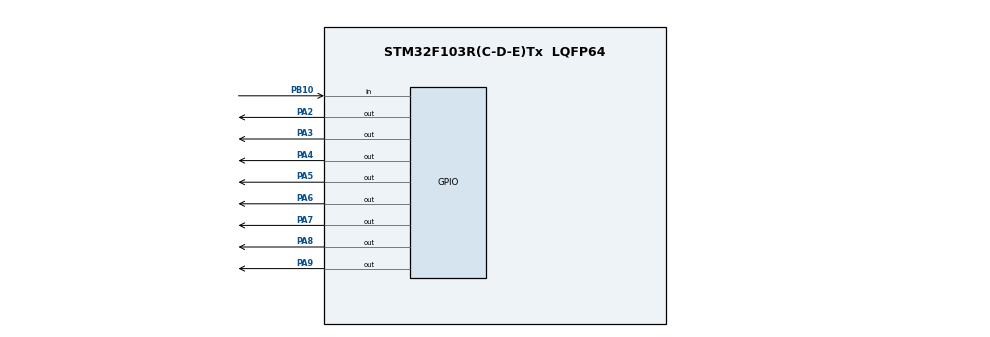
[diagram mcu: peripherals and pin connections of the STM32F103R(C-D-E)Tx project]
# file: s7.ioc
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Mcu.Family=STM32F1
Mcu.Name=STM32F103R(C-D-E)Tx
Mcu.Package=LQFP64
NVIC.PriorityGroup=NVIC_PRIORITYGROUP_4
PA2.Signal=GPIO_Output
PA3.Signal=GPIO_Output
PA4.Signal=GPIO_Output
PA5.Signal=GPIO_Output
PA6.Signal=GPIO_Output
PA7.Signal=GPIO_Output
PA8.Signal=GPIO_Output
PA9.Signal=GPIO_Output
PB10.GPIO_PuPd=GPIO_PULLUP
PB10.Signal=GPIO_Input
ProjectManager.TargetToolchain=EWARM
RCC.APB1Freq_Value=8000000
RCC.APB2Freq_Value=8000000
board=s7

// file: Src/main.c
/**
  ******************************************************************************
  * File Name          : main.c
  * Description        : Main program body
  ******************************************************************************
  *
  * COPYRIGHT(c) 2016 STMicroelectronics
  *
  * Redistribution and use in source and binary forms, with or without modification,
  * are permitted provided that the following conditions are met:
  *   1. Redistributions of source code must retain the above copyright notice,
  *      this list of conditions and the following disclaimer.
  *   2. Redistributions in binary form must reproduce the above copyright notice,
  *      this list of conditions and the following disclaimer in the documentation
  *      and/or other materials provided with the distribution.
  *   3. Neither the name of STMicroelectronics nor the names of its contributors
  *      may be used to endorse or promote products derived from this software
  *      without specific prior written permission.
  *
  * THIS SOFTWARE IS PROVIDED BY THE COPYRIGHT HOLDERS AND CONTRIBUTORS "AS IS"
  * AND ANY EXPRESS OR IMPLIED WARRANTIES, INCLUDING, BUT NOT LIMITED TO, THE
  * IMPLIED WARRANTIES OF MERCHANTABILITY AND FITNESS FOR A PARTICULAR PURPOSE ARE
  * DISCLAIMED. IN NO EVENT SHALL THE COPYRIGHT HOLDER OR CONTRIBUTORS BE LIABLE
  * FOR ANY DIRECT, INDIRECT, INCIDENTAL, SPECIAL, EXEMPLARY, OR CONSEQUENTIAL
  * DAMAGES (INCLUDING, BUT NOT LIMITED TO, PROCUREMENT OF SUBSTITUTE GOODS OR
  * SERVICES; LOSS OF USE, DATA, OR PROFITS; OR BUSINESS INTERRUPTION) HOWEVER
  * CAUSED AND ON ANY THEORY OF LIABILITY, WHETHER IN CONTRACT, STRICT LIABILITY,
  * OR TORT (INCLUDING NEGLIGENCE OR OTHERWISE) ARISING IN ANY WAY OUT OF THE USE
  * OF THIS SOFTWARE, EVEN IF ADVISED OF THE POSSIBILITY OF SUCH DAMAGE.
  *
  ******************************************************************************
  */
#include "stm32f1xx_hal.h"

/* USER CODE BEGIN PV */
/* Private variables ---------------------------------------------------------*/

/* USER CODE END PV */

void SystemClock_Config(void);
static void MX_GPIO_Init(void);

/* USER CODE BEGIN PFP */
/* Private function prototypes -----------------------------------------------*/

/* USER CODE END PFP */

/* USER CODE BEGIN 0 */

const unsigned char data[10]={0x3F, 0x06, 0x5b, 0x4f, 0x66,
                              0x6d, 0x7d, 0x07, 0x7f, 0x6f,};
unsigned char i;

/* USER CODE END 0 */

int main(void)
{

  /* MCU Configuration----------------------------------------------------------*/

  /* Reset of all peripherals, Initializes the Flash interface and the Systick. */
  HAL_Init();

  /* Configure the system clock */
  SystemClock_Config();

  /* Initialize all configured peripherals */
  MX_GPIO_Init();

  /* Infinite loop */
  /* USER CODE BEGIN WHILE */
  while (1)
  {

      HAL_GPIO_WritePin(GPIOA, (0xFF<<2), GPIO_PIN_RESET);
      HAL_GPIO_WritePin(GPIOA, (data[i]<<2), GPIO_PIN_SET);

      if (HAL_GPIO_ReadPin(GPIOB,GPIO_PIN_10)==0)
      {
        HAL_Delay(200);
        i++;
        if(i==10)
          i=0;
      }
  /* USER CODE END WHILE */

  }

}

/** System Clock Configuration
*/
void SystemClock_Config(void)
{

  RCC_OscInitTypeDef RCC_OscInitStruct;
  RCC_ClkInitTypeDef RCC_ClkInitStruct;

  RCC_OscInitStruct.OscillatorType = RCC_OSCILLATORTYPE_HSI;
  RCC_OscInitStruct.HSIState = RCC_HSI_ON;
  RCC_OscInitStruct.HSICalibrationValue = 16;
  RCC_OscInitStruct.PLL.PLLState = RCC_PLL_NONE;
  HAL_RCC_OscConfig(&RCC_OscInitStruct);

  RCC_ClkInitStruct.ClockType = RCC_CLOCKTYPE_SYSCLK;
  RCC_ClkInitStruct.SYSCLKSource = RCC_SYSCLKSOURCE_HSI;
  RCC_ClkInitStruct.AHBCLKDivider = RCC_SYSCLK_DIV1;
  RCC_ClkInitStruct.APB1CLKDivider = RCC_HCLK_DIV1;
  RCC_ClkInitStruct.APB2CLKDivider = RCC_HCLK_DIV1;
  HAL_RCC_ClockConfig(&RCC_ClkInitStruct, FLASH_LATENCY_0);

  HAL_SYSTICK_Config(HAL_RCC_GetHCLKFreq()/1000);

  HAL_SYSTICK_CLKSourceConfig(SYSTICK_CLKSOURCE_HCLK);

  /* SysTick_IRQn interrupt configuration */
  HAL_NVIC_SetPriority(SysTick_IRQn, 0, 0);
}

/** Configure pins as
        * Analog
        * Input
        * Output
        * EVENT_OUT
        * EXTI
*/
void MX_GPIO_Init(void)
{

  GPIO_InitTypeDef GPIO_InitStruct;

  /* GPIO Ports Clock Enable */
  __GPIOA_CLK_ENABLE();
  __GPIOB_CLK_ENABLE();

  /*Configure GPIO pins : PA2 PA3 PA4 PA5
                           PA6 PA7 PA8 PA9 */
  GPIO_InitStruct.Pin = GPIO_PIN_2|GPIO_PIN_3|GPIO_PIN_4|GPIO_PIN_5
                          |GPIO_PIN_6|GPIO_PIN_7|GPIO_PIN_8|GPIO_PIN_9;
  GPIO_InitStruct.Mode = GPIO_MODE_OUTPUT_PP;
  GPIO_InitStruct.Speed = GPIO_SPEED_LOW;
  HAL_GPIO_Init(GPIOA, &GPIO_InitStruct);

  /*Configure GPIO pin : PB10 */
  GPIO_InitStruct.Pin = GPIO_PIN_10;
  GPIO_InitStruct.Mode = GPIO_MODE_INPUT;
  GPIO_InitStruct.Pull = GPIO_PULLUP;
  HAL_GPIO_Init(GPIOB, &GPIO_InitStruct);

}

/************************ (C) COPYRIGHT STMicroelectronics *****END OF FILE****/
